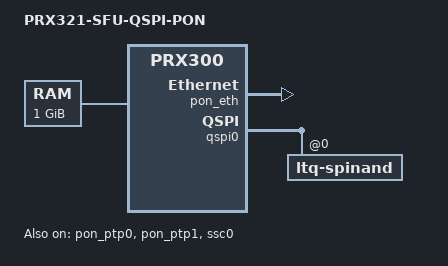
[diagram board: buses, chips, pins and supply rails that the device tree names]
/dts-v1/;
#include "prx321-sfu-12.dtsi"

/ {
	model = "PRX321-SFU-QSPI-PON";
	compatible = "intel,prx321-sfu-qspi-pon", "intel,prx321-sfu", "intel,prx300";

	chosen {
		stdout-path = "serial0";
	};

	memory@0 {
		device_type = "memory";
		reg = <0x20000000 0x40000000>; /* 1024 MB */
	};
};

&pon_eth {
	status = "okay";
};

&pon_ptp0 {
	status = "okay";
};

&pon_ptp1 {
	status = "okay";
};

&ponmbox1 {
	status = "okay";
};

/* For voice enable the SPI driver needed for access to the on silicon VCODEC but prevent switching the pinmux to this SPI bus. On this design these pins are used for the QSPI bus. */
&ssc0 {
	status = "okay";
	/delete-property/ pinctrl-names;
	/delete-property/ pinctrl-0;
};

&qspi0 {
	status = "okay";
	ltq-spinand@0 {
		status = "okay";
	};
};
